VERSION ""

NS_ :

BS_:

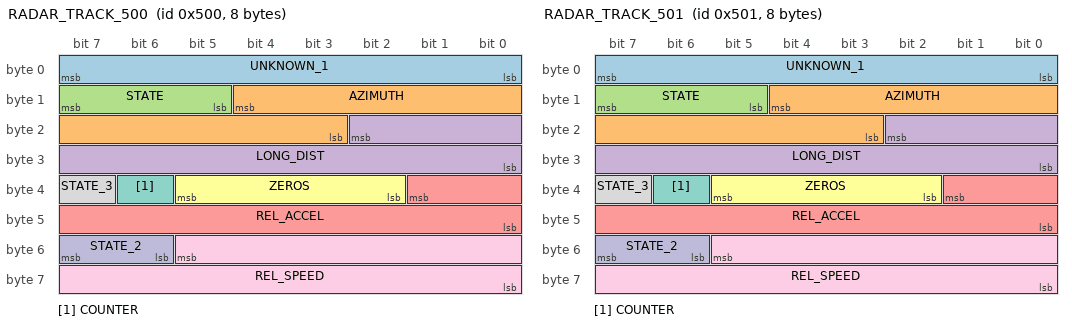
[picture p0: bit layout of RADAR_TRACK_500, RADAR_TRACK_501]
BO_ 1280 RADAR_TRACK_500: 8 RADAR
 SG_ UNKNOWN_1 : 7|8@0- (1,0) [-128|127] "" XXX
 SG_ AZIMUTH : 12|10@0- (0.2,0) [-102.4|102.2] "" XXX
 SG_ STATE : 15|3@0+ (1,0) [0|7] "" XXX
 SG_ LONG_DIST : 18|11@0+ (0.1,0) [0|204.7] "" XXX
 SG_ REL_ACCEL : 33|10@0- (0.02,0) [-10.24|10.22] "" XXX
 SG_ ZEROS : 37|4@0+ (1,0) [0|255] "" XXX
 SG_ COUNTER : 38|1@0+ (1,0) [0|1] "" XXX
 SG_ STATE_3 : 39|1@0+ (1,0) [0|1] "" XXX
 SG_ REL_SPEED : 53|14@0- (0.01,0) [-81.92|81.92] "" XXX
 SG_ STATE_2 : 55|2@0+ (1,0) [0|3] "" XXX

BO_ 1281 RADAR_TRACK_501: 8 RADAR
 SG_ UNKNOWN_1 : 7|8@0- (1,0) [-128|127] "" XXX
 SG_ AZIMUTH : 12|10@0- (0.2,0) [-102.4|102.2] "" XXX
 SG_ STATE : 15|3@0+ (1,0) [0|7] "" XXX
 SG_ LONG_DIST : 18|11@0+ (0.1,0) [0|204.7] "" XXX
 SG_ REL_ACCEL : 33|10@0- (0.02,0) [-10.24|10.22] "" XXX
 SG_ ZEROS : 37|4@0+ (1,0) [0|255] "" XXX
 SG_ COUNTER : 38|1@0+ (1,0) [0|1] "" XXX
 SG_ STATE_3 : 39|1@0+ (1,0) [0|1] "" XXX
 SG_ REL_SPEED : 53|14@0- (0.01,0) [-81.92|81.92] "" XXX
 SG_ STATE_2 : 55|2@0+ (1,0) [0|3] "" XXX

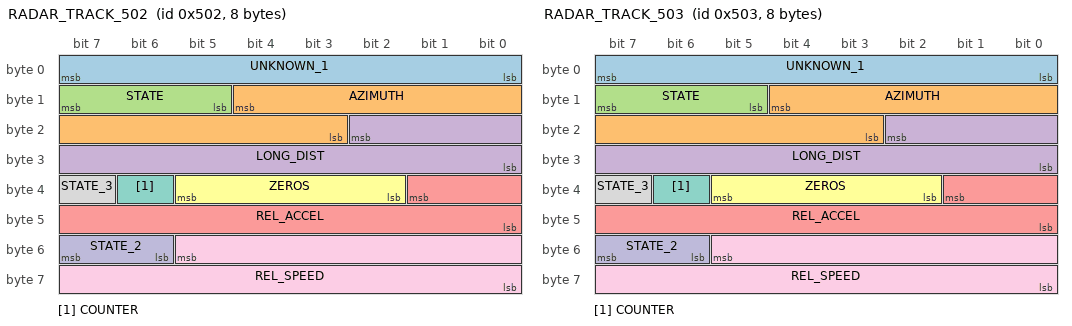
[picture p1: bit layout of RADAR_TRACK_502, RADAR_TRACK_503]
BO_ 1282 RADAR_TRACK_502: 8 RADAR
 SG_ UNKNOWN_1 : 7|8@0- (1,0) [-128|127] "" XXX
 SG_ AZIMUTH : 12|10@0- (0.2,0) [-102.4|102.2] "" XXX
 SG_ STATE : 15|3@0+ (1,0) [0|7] "" XXX
 SG_ LONG_DIST : 18|11@0+ (0.1,0) [0|204.7] "" XXX
 SG_ REL_ACCEL : 33|10@0- (0.02,0) [-10.24|10.22] "" XXX
 SG_ ZEROS : 37|4@0+ (1,0) [0|255] "" XXX
 SG_ COUNTER : 38|1@0+ (1,0) [0|1] "" XXX
 SG_ STATE_3 : 39|1@0+ (1,0) [0|1] "" XXX
 SG_ REL_SPEED : 53|14@0- (0.01,0) [-81.92|81.92] "" XXX
 SG_ STATE_2 : 55|2@0+ (1,0) [0|3] "" XXX

BO_ 1283 RADAR_TRACK_503: 8 RADAR
 SG_ UNKNOWN_1 : 7|8@0- (1,0) [-128|127] "" XXX
 SG_ AZIMUTH : 12|10@0- (0.2,0) [-102.4|102.2] "" XXX
 SG_ STATE : 15|3@0+ (1,0) [0|7] "" XXX
 SG_ LONG_DIST : 18|11@0+ (0.1,0) [0|204.7] "" XXX
 SG_ REL_ACCEL : 33|10@0- (0.02,0) [-10.24|10.22] "" XXX
 SG_ ZEROS : 37|4@0+ (1,0) [0|255] "" XXX
 SG_ COUNTER : 38|1@0+ (1,0) [0|1] "" XXX
 SG_ STATE_3 : 39|1@0+ (1,0) [0|1] "" XXX
 SG_ REL_SPEED : 53|14@0- (0.01,0) [-81.92|81.92] "" XXX
 SG_ STATE_2 : 55|2@0+ (1,0) [0|3] "" XXX

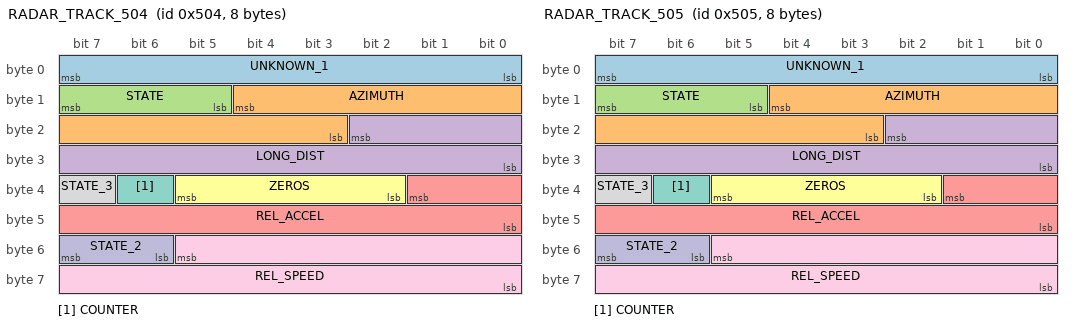
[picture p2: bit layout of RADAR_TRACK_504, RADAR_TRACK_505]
BO_ 1284 RADAR_TRACK_504: 8 RADAR
 SG_ UNKNOWN_1 : 7|8@0- (1,0) [-128|127] "" XXX
 SG_ AZIMUTH : 12|10@0- (0.2,0) [-102.4|102.2] "" XXX
 SG_ STATE : 15|3@0+ (1,0) [0|7] "" XXX
 SG_ LONG_DIST : 18|11@0+ (0.1,0) [0|204.7] "" XXX
 SG_ REL_ACCEL : 33|10@0- (0.02,0) [-10.24|10.22] "" XXX
 SG_ ZEROS : 37|4@0+ (1,0) [0|255] "" XXX
 SG_ COUNTER : 38|1@0+ (1,0) [0|1] "" XXX
 SG_ STATE_3 : 39|1@0+ (1,0) [0|1] "" XXX
 SG_ REL_SPEED : 53|14@0- (0.01,0) [-81.92|81.92] "" XXX
 SG_ STATE_2 : 55|2@0+ (1,0) [0|3] "" XXX

BO_ 1285 RADAR_TRACK_505: 8 RADAR
 SG_ UNKNOWN_1 : 7|8@0- (1,0) [-128|127] "" XXX
 SG_ AZIMUTH : 12|10@0- (0.2,0) [-102.4|102.2] "" XXX
 SG_ STATE : 15|3@0+ (1,0) [0|7] "" XXX
 SG_ LONG_DIST : 18|11@0+ (0.1,0) [0|204.7] "" XXX
 SG_ REL_ACCEL : 33|10@0- (0.02,0) [-10.24|10.22] "" XXX
 SG_ ZEROS : 37|4@0+ (1,0) [0|255] "" XXX
 SG_ COUNTER : 38|1@0+ (1,0) [0|1] "" XXX
 SG_ STATE_3 : 39|1@0+ (1,0) [0|1] "" XXX
 SG_ REL_SPEED : 53|14@0- (0.01,0) [-81.92|81.92] "" XXX
 SG_ STATE_2 : 55|2@0+ (1,0) [0|3] "" XXX

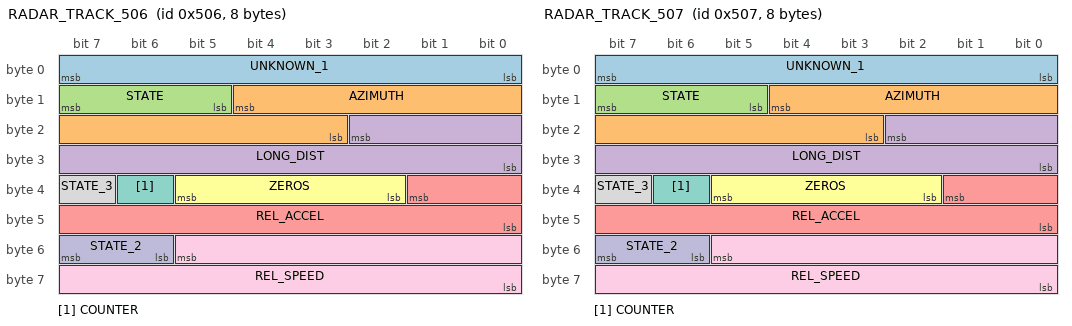
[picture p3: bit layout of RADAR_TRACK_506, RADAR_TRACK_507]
BO_ 1286 RADAR_TRACK_506: 8 RADAR
 SG_ UNKNOWN_1 : 7|8@0- (1,0) [-128|127] "" XXX
 SG_ AZIMUTH : 12|10@0- (0.2,0) [-102.4|102.2] "" XXX
 SG_ STATE : 15|3@0+ (1,0) [0|7] "" XXX
 SG_ LONG_DIST : 18|11@0+ (0.1,0) [0|204.7] "" XXX
 SG_ REL_ACCEL : 33|10@0- (0.02,0) [-10.24|10.22] "" XXX
 SG_ ZEROS : 37|4@0+ (1,0) [0|255] "" XXX
 SG_ COUNTER : 38|1@0+ (1,0) [0|1] "" XXX
 SG_ STATE_3 : 39|1@0+ (1,0) [0|1] "" XXX
 SG_ REL_SPEED : 53|14@0- (0.01,0) [-81.92|81.92] "" XXX
 SG_ STATE_2 : 55|2@0+ (1,0) [0|3] "" XXX

BO_ 1287 RADAR_TRACK_507: 8 RADAR
 SG_ UNKNOWN_1 : 7|8@0- (1,0) [-128|127] "" XXX
 SG_ AZIMUTH : 12|10@0- (0.2,0) [-102.4|102.2] "" XXX
 SG_ STATE : 15|3@0+ (1,0) [0|7] "" XXX
 SG_ LONG_DIST : 18|11@0+ (0.1,0) [0|204.7] "" XXX
 SG_ REL_ACCEL : 33|10@0- (0.02,0) [-10.24|10.22] "" XXX
 SG_ ZEROS : 37|4@0+ (1,0) [0|255] "" XXX
 SG_ COUNTER : 38|1@0+ (1,0) [0|1] "" XXX
 SG_ STATE_3 : 39|1@0+ (1,0) [0|1] "" XXX
 SG_ REL_SPEED : 53|14@0- (0.01,0) [-81.92|81.92] "" XXX
 SG_ STATE_2 : 55|2@0+ (1,0) [0|3] "" XXX

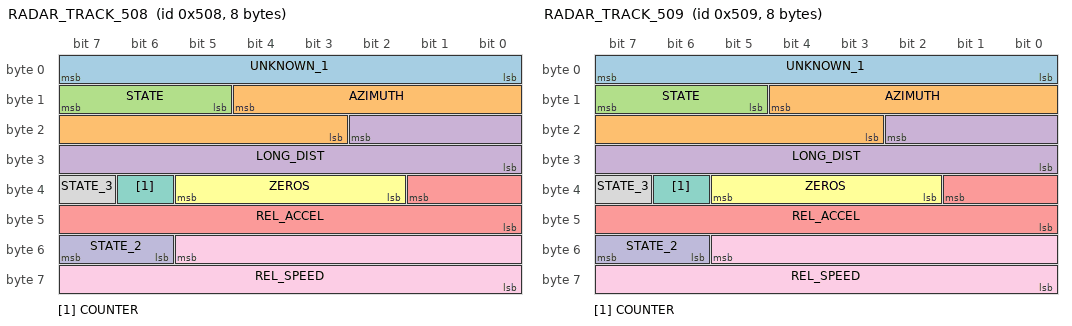
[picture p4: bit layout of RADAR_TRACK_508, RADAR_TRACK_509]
BO_ 1288 RADAR_TRACK_508: 8 RADAR
 SG_ UNKNOWN_1 : 7|8@0- (1,0) [-128|127] "" XXX
 SG_ AZIMUTH : 12|10@0- (0.2,0) [-102.4|102.2] "" XXX
 SG_ STATE : 15|3@0+ (1,0) [0|7] "" XXX
 SG_ LONG_DIST : 18|11@0+ (0.1,0) [0|204.7] "" XXX
 SG_ REL_ACCEL : 33|10@0- (0.02,0) [-10.24|10.22] "" XXX
 SG_ ZEROS : 37|4@0+ (1,0) [0|255] "" XXX
 SG_ COUNTER : 38|1@0+ (1,0) [0|1] "" XXX
 SG_ STATE_3 : 39|1@0+ (1,0) [0|1] "" XXX
 SG_ REL_SPEED : 53|14@0- (0.01,0) [-81.92|81.92] "" XXX
 SG_ STATE_2 : 55|2@0+ (1,0) [0|3] "" XXX

BO_ 1289 RADAR_TRACK_509: 8 RADAR
 SG_ UNKNOWN_1 : 7|8@0- (1,0) [-128|127] "" XXX
 SG_ AZIMUTH : 12|10@0- (0.2,0) [-102.4|102.2] "" XXX
 SG_ STATE : 15|3@0+ (1,0) [0|7] "" XXX
 SG_ LONG_DIST : 18|11@0+ (0.1,0) [0|204.7] "" XXX
 SG_ REL_ACCEL : 33|10@0- (0.02,0) [-10.24|10.22] "" XXX
 SG_ ZEROS : 37|4@0+ (1,0) [0|255] "" XXX
 SG_ COUNTER : 38|1@0+ (1,0) [0|1] "" XXX
 SG_ STATE_3 : 39|1@0+ (1,0) [0|1] "" XXX
 SG_ REL_SPEED : 53|14@0- (0.01,0) [-81.92|81.92] "" XXX
 SG_ STATE_2 : 55|2@0+ (1,0) [0|3] "" XXX

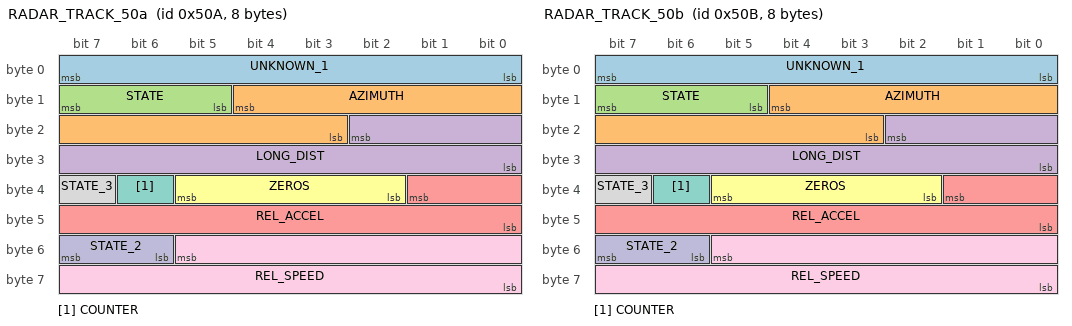
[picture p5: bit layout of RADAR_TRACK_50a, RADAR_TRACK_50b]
BO_ 1290 RADAR_TRACK_50a: 8 RADAR
 SG_ UNKNOWN_1 : 7|8@0- (1,0) [-128|127] "" XXX
 SG_ AZIMUTH : 12|10@0- (0.2,0) [-102.4|102.2] "" XXX
 SG_ STATE : 15|3@0+ (1,0) [0|7] "" XXX
 SG_ LONG_DIST : 18|11@0+ (0.1,0) [0|204.7] "" XXX
 SG_ REL_ACCEL : 33|10@0- (0.02,0) [-10.24|10.22] "" XXX
 SG_ ZEROS : 37|4@0+ (1,0) [0|255] "" XXX
 SG_ COUNTER : 38|1@0+ (1,0) [0|1] "" XXX
 SG_ STATE_3 : 39|1@0+ (1,0) [0|1] "" XXX
 SG_ REL_SPEED : 53|14@0- (0.01,0) [-81.92|81.92] "" XXX
 SG_ STATE_2 : 55|2@0+ (1,0) [0|3] "" XXX

BO_ 1291 RADAR_TRACK_50b: 8 RADAR
 SG_ UNKNOWN_1 : 7|8@0- (1,0) [-128|127] "" XXX
 SG_ AZIMUTH : 12|10@0- (0.2,0) [-102.4|102.2] "" XXX
 SG_ STATE : 15|3@0+ (1,0) [0|7] "" XXX
 SG_ LONG_DIST : 18|11@0+ (0.1,0) [0|204.7] "" XXX
 SG_ REL_ACCEL : 33|10@0- (0.02,0) [-10.24|10.22] "" XXX
 SG_ ZEROS : 37|4@0+ (1,0) [0|255] "" XXX
 SG_ COUNTER : 38|1@0+ (1,0) [0|1] "" XXX
 SG_ STATE_3 : 39|1@0+ (1,0) [0|1] "" XXX
 SG_ REL_SPEED : 53|14@0- (0.01,0) [-81.92|81.92] "" XXX
 SG_ STATE_2 : 55|2@0+ (1,0) [0|3] "" XXX

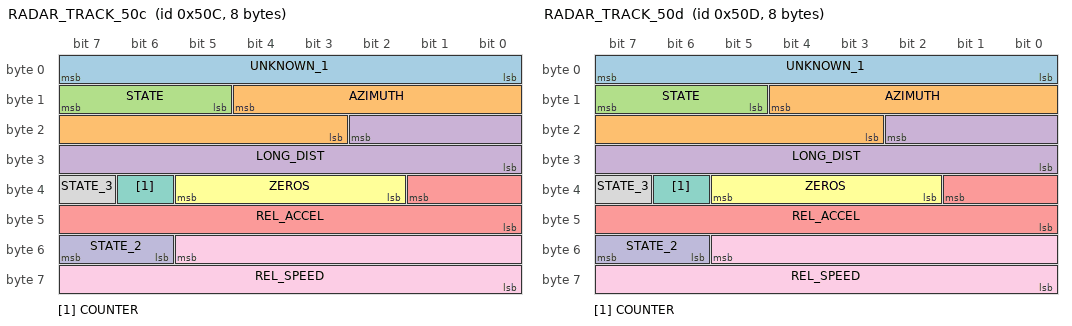
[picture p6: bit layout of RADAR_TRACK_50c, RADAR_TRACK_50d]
BO_ 1292 RADAR_TRACK_50c: 8 RADAR
 SG_ UNKNOWN_1 : 7|8@0- (1,0) [-128|127] "" XXX
 SG_ AZIMUTH : 12|10@0- (0.2,0) [-102.4|102.2] "" XXX
 SG_ STATE : 15|3@0+ (1,0) [0|7] "" XXX
 SG_ LONG_DIST : 18|11@0+ (0.1,0) [0|204.7] "" XXX
 SG_ REL_ACCEL : 33|10@0- (0.02,0) [-10.24|10.22] "" XXX
 SG_ ZEROS : 37|4@0+ (1,0) [0|255] "" XXX
 SG_ COUNTER : 38|1@0+ (1,0) [0|1] "" XXX
 SG_ STATE_3 : 39|1@0+ (1,0) [0|1] "" XXX
 SG_ REL_SPEED : 53|14@0- (0.01,0) [-81.92|81.92] "" XXX
 SG_ STATE_2 : 55|2@0+ (1,0) [0|3] "" XXX

BO_ 1293 RADAR_TRACK_50d: 8 RADAR
 SG_ UNKNOWN_1 : 7|8@0- (1,0) [-128|127] "" XXX
 SG_ AZIMUTH : 12|10@0- (0.2,0) [-102.4|102.2] "" XXX
 SG_ STATE : 15|3@0+ (1,0) [0|7] "" XXX
 SG_ LONG_DIST : 18|11@0+ (0.1,0) [0|204.7] "" XXX
 SG_ REL_ACCEL : 33|10@0- (0.02,0) [-10.24|10.22] "" XXX
 SG_ ZEROS : 37|4@0+ (1,0) [0|255] "" XXX
 SG_ COUNTER : 38|1@0+ (1,0) [0|1] "" XXX
 SG_ STATE_3 : 39|1@0+ (1,0) [0|1] "" XXX
 SG_ REL_SPEED : 53|14@0- (0.01,0) [-81.92|81.92] "" XXX
 SG_ STATE_2 : 55|2@0+ (1,0) [0|3] "" XXX

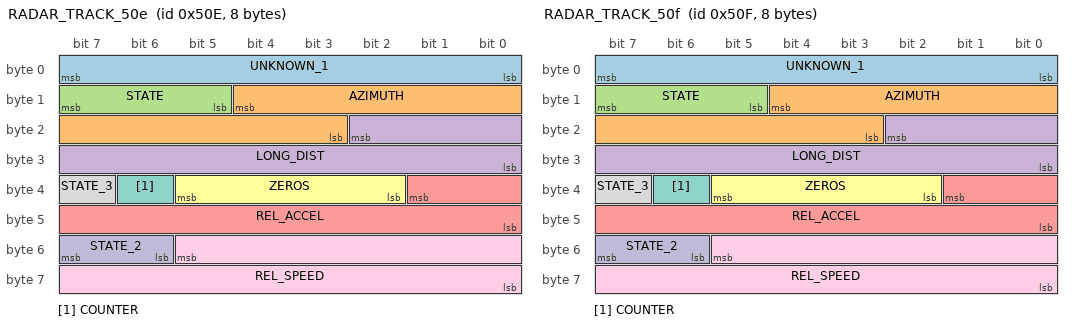
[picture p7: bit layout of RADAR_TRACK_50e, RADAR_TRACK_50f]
BO_ 1294 RADAR_TRACK_50e: 8 RADAR
 SG_ UNKNOWN_1 : 7|8@0- (1,0) [-128|127] "" XXX
 SG_ AZIMUTH : 12|10@0- (0.2,0) [-102.4|102.2] "" XXX
 SG_ STATE : 15|3@0+ (1,0) [0|7] "" XXX
 SG_ LONG_DIST : 18|11@0+ (0.1,0) [0|204.7] "" XXX
 SG_ REL_ACCEL : 33|10@0- (0.02,0) [-10.24|10.22] "" XXX
 SG_ ZEROS : 37|4@0+ (1,0) [0|255] "" XXX
 SG_ COUNTER : 38|1@0+ (1,0) [0|1] "" XXX
 SG_ STATE_3 : 39|1@0+ (1,0) [0|1] "" XXX
 SG_ REL_SPEED : 53|14@0- (0.01,0) [-81.92|81.92] "" XXX
 SG_ STATE_2 : 55|2@0+ (1,0) [0|3] "" XXX

BO_ 1295 RADAR_TRACK_50f: 8 RADAR
 SG_ UNKNOWN_1 : 7|8@0- (1,0) [-128|127] "" XXX
 SG_ AZIMUTH : 12|10@0- (0.2,0) [-102.4|102.2] "" XXX
 SG_ STATE : 15|3@0+ (1,0) [0|7] "" XXX
 SG_ LONG_DIST : 18|11@0+ (0.1,0) [0|204.7] "" XXX
 SG_ REL_ACCEL : 33|10@0- (0.02,0) [-10.24|10.22] "" XXX
 SG_ ZEROS : 37|4@0+ (1,0) [0|255] "" XXX
 SG_ COUNTER : 38|1@0+ (1,0) [0|1] "" XXX
 SG_ STATE_3 : 39|1@0+ (1,0) [0|1] "" XXX
 SG_ REL_SPEED : 53|14@0- (0.01,0) [-81.92|81.92] "" XXX
 SG_ STATE_2 : 55|2@0+ (1,0) [0|3] "" XXX

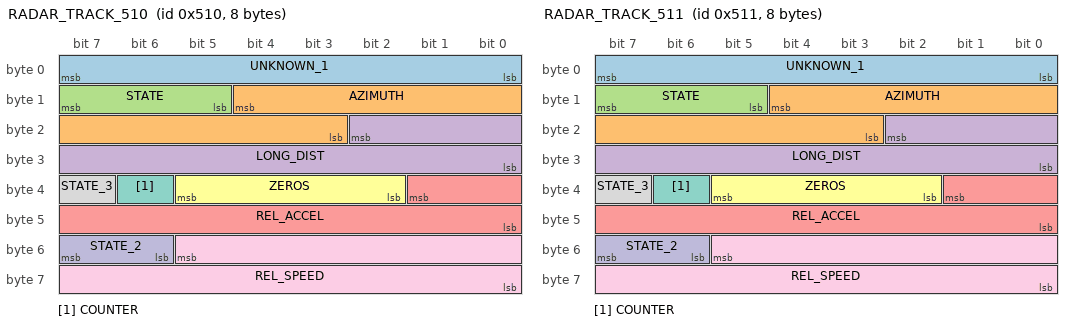
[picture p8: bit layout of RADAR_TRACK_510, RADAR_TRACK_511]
BO_ 1296 RADAR_TRACK_510: 8 RADAR
 SG_ UNKNOWN_1 : 7|8@0- (1,0) [-128|127] "" XXX
 SG_ AZIMUTH : 12|10@0- (0.2,0) [-102.4|102.2] "" XXX
 SG_ STATE : 15|3@0+ (1,0) [0|7] "" XXX
 SG_ LONG_DIST : 18|11@0+ (0.1,0) [0|204.7] "" XXX
 SG_ REL_ACCEL : 33|10@0- (0.02,0) [-10.24|10.22] "" XXX
 SG_ ZEROS : 37|4@0+ (1,0) [0|255] "" XXX
 SG_ COUNTER : 38|1@0+ (1,0) [0|1] "" XXX
 SG_ STATE_3 : 39|1@0+ (1,0) [0|1] "" XXX
 SG_ REL_SPEED : 53|14@0- (0.01,0) [-81.92|81.92] "" XXX
 SG_ STATE_2 : 55|2@0+ (1,0) [0|3] "" XXX

BO_ 1297 RADAR_TRACK_511: 8 RADAR
 SG_ UNKNOWN_1 : 7|8@0- (1,0) [-128|127] "" XXX
 SG_ AZIMUTH : 12|10@0- (0.2,0) [-102.4|102.2] "" XXX
 SG_ STATE : 15|3@0+ (1,0) [0|7] "" XXX
 SG_ LONG_DIST : 18|11@0+ (0.1,0) [0|204.7] "" XXX
 SG_ REL_ACCEL : 33|10@0- (0.02,0) [-10.24|10.22] "" XXX
 SG_ ZEROS : 37|4@0+ (1,0) [0|255] "" XXX
 SG_ COUNTER : 38|1@0+ (1,0) [0|1] "" XXX
 SG_ STATE_3 : 39|1@0+ (1,0) [0|1] "" XXX
 SG_ REL_SPEED : 53|14@0- (0.01,0) [-81.92|81.92] "" XXX
 SG_ STATE_2 : 55|2@0+ (1,0) [0|3] "" XXX

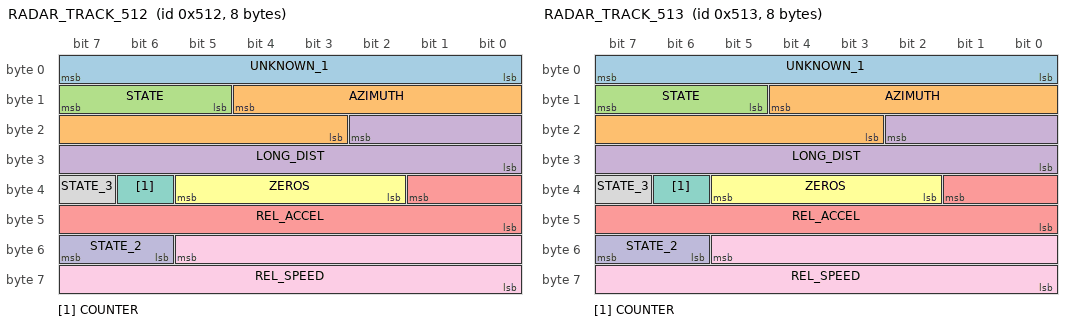
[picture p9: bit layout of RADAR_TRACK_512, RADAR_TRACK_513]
BO_ 1298 RADAR_TRACK_512: 8 RADAR
 SG_ UNKNOWN_1 : 7|8@0- (1,0) [-128|127] "" XXX
 SG_ AZIMUTH : 12|10@0- (0.2,0) [-102.4|102.2] "" XXX
 SG_ STATE : 15|3@0+ (1,0) [0|7] "" XXX
 SG_ LONG_DIST : 18|11@0+ (0.1,0) [0|204.7] "" XXX
 SG_ REL_ACCEL : 33|10@0- (0.02,0) [-10.24|10.22] "" XXX
 SG_ ZEROS : 37|4@0+ (1,0) [0|255] "" XXX
 SG_ COUNTER : 38|1@0+ (1,0) [0|1] "" XXX
 SG_ STATE_3 : 39|1@0+ (1,0) [0|1] "" XXX
 SG_ REL_SPEED : 53|14@0- (0.01,0) [-81.92|81.92] "" XXX
 SG_ STATE_2 : 55|2@0+ (1,0) [0|3] "" XXX

BO_ 1299 RADAR_TRACK_513: 8 RADAR
 SG_ UNKNOWN_1 : 7|8@0- (1,0) [-128|127] "" XXX
 SG_ AZIMUTH : 12|10@0- (0.2,0) [-102.4|102.2] "" XXX
 SG_ STATE : 15|3@0+ (1,0) [0|7] "" XXX
 SG_ LONG_DIST : 18|11@0+ (0.1,0) [0|204.7] "" XXX
 SG_ REL_ACCEL : 33|10@0- (0.02,0) [-10.24|10.22] "" XXX
 SG_ ZEROS : 37|4@0+ (1,0) [0|255] "" XXX
 SG_ COUNTER : 38|1@0+ (1,0) [0|1] "" XXX
 SG_ STATE_3 : 39|1@0+ (1,0) [0|1] "" XXX
 SG_ REL_SPEED : 53|14@0- (0.01,0) [-81.92|81.92] "" XXX
 SG_ STATE_2 : 55|2@0+ (1,0) [0|3] "" XXX

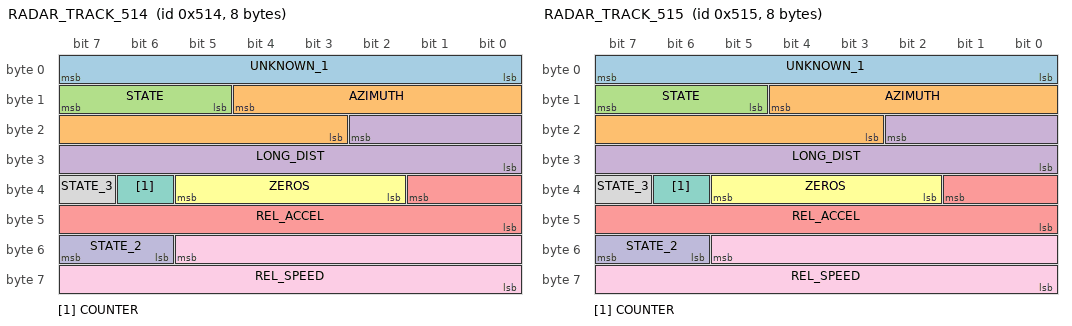
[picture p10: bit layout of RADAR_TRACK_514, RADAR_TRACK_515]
BO_ 1300 RADAR_TRACK_514: 8 RADAR
 SG_ UNKNOWN_1 : 7|8@0- (1,0) [-128|127] "" XXX
 SG_ AZIMUTH : 12|10@0- (0.2,0) [-102.4|102.2] "" XXX
 SG_ STATE : 15|3@0+ (1,0) [0|7] "" XXX
 SG_ LONG_DIST : 18|11@0+ (0.1,0) [0|204.7] "" XXX
 SG_ REL_ACCEL : 33|10@0- (0.02,0) [-10.24|10.22] "" XXX
 SG_ ZEROS : 37|4@0+ (1,0) [0|255] "" XXX
 SG_ COUNTER : 38|1@0+ (1,0) [0|1] "" XXX
 SG_ STATE_3 : 39|1@0+ (1,0) [0|1] "" XXX
 SG_ REL_SPEED : 53|14@0- (0.01,0) [-81.92|81.92] "" XXX
 SG_ STATE_2 : 55|2@0+ (1,0) [0|3] "" XXX

BO_ 1301 RADAR_TRACK_515: 8 RADAR
 SG_ UNKNOWN_1 : 7|8@0- (1,0) [-128|127] "" XXX
 SG_ AZIMUTH : 12|10@0- (0.2,0) [-102.4|102.2] "" XXX
 SG_ STATE : 15|3@0+ (1,0) [0|7] "" XXX
 SG_ LONG_DIST : 18|11@0+ (0.1,0) [0|204.7] "" XXX
 SG_ REL_ACCEL : 33|10@0- (0.02,0) [-10.24|10.22] "" XXX
 SG_ ZEROS : 37|4@0+ (1,0) [0|255] "" XXX
 SG_ COUNTER : 38|1@0+ (1,0) [0|1] "" XXX
 SG_ STATE_3 : 39|1@0+ (1,0) [0|1] "" XXX
 SG_ REL_SPEED : 53|14@0- (0.01,0) [-81.92|81.92] "" XXX
 SG_ STATE_2 : 55|2@0+ (1,0) [0|3] "" XXX

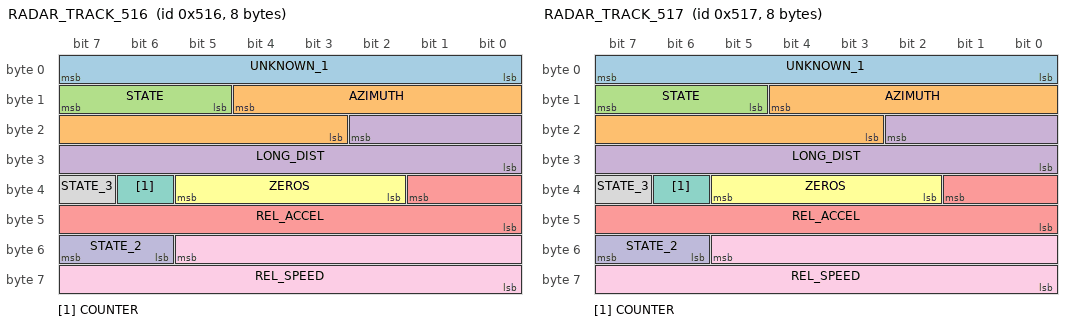
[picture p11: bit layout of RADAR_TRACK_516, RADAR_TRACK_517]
BO_ 1302 RADAR_TRACK_516: 8 RADAR
 SG_ UNKNOWN_1 : 7|8@0- (1,0) [-128|127] "" XXX
 SG_ AZIMUTH : 12|10@0- (0.2,0) [-102.4|102.2] "" XXX
 SG_ STATE : 15|3@0+ (1,0) [0|7] "" XXX
 SG_ LONG_DIST : 18|11@0+ (0.1,0) [0|204.7] "" XXX
 SG_ REL_ACCEL : 33|10@0- (0.02,0) [-10.24|10.22] "" XXX
 SG_ ZEROS : 37|4@0+ (1,0) [0|255] "" XXX
 SG_ COUNTER : 38|1@0+ (1,0) [0|1] "" XXX
 SG_ STATE_3 : 39|1@0+ (1,0) [0|1] "" XXX
 SG_ REL_SPEED : 53|14@0- (0.01,0) [-81.92|81.92] "" XXX
 SG_ STATE_2 : 55|2@0+ (1,0) [0|3] "" XXX

BO_ 1303 RADAR_TRACK_517: 8 RADAR
 SG_ UNKNOWN_1 : 7|8@0- (1,0) [-128|127] "" XXX
 SG_ AZIMUTH : 12|10@0- (0.2,0) [-102.4|102.2] "" XXX
 SG_ STATE : 15|3@0+ (1,0) [0|7] "" XXX
 SG_ LONG_DIST : 18|11@0+ (0.1,0) [0|204.7] "" XXX
 SG_ REL_ACCEL : 33|10@0- (0.02,0) [-10.24|10.22] "" XXX
 SG_ ZEROS : 37|4@0+ (1,0) [0|255] "" XXX
 SG_ COUNTER : 38|1@0+ (1,0) [0|1] "" XXX
 SG_ STATE_3 : 39|1@0+ (1,0) [0|1] "" XXX
 SG_ REL_SPEED : 53|14@0- (0.01,0) [-81.92|81.92] "" XXX
 SG_ STATE_2 : 55|2@0+ (1,0) [0|3] "" XXX

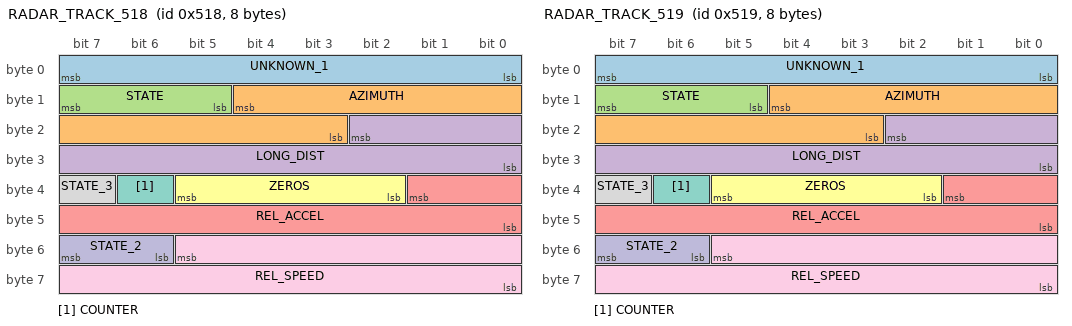
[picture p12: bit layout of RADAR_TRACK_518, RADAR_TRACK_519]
BO_ 1304 RADAR_TRACK_518: 8 RADAR
 SG_ UNKNOWN_1 : 7|8@0- (1,0) [-128|127] "" XXX
 SG_ AZIMUTH : 12|10@0- (0.2,0) [-102.4|102.2] "" XXX
 SG_ STATE : 15|3@0+ (1,0) [0|7] "" XXX
 SG_ LONG_DIST : 18|11@0+ (0.1,0) [0|204.7] "" XXX
 SG_ REL_ACCEL : 33|10@0- (0.02,0) [-10.24|10.22] "" XXX
 SG_ ZEROS : 37|4@0+ (1,0) [0|255] "" XXX
 SG_ COUNTER : 38|1@0+ (1,0) [0|1] "" XXX
 SG_ STATE_3 : 39|1@0+ (1,0) [0|1] "" XXX
 SG_ REL_SPEED : 53|14@0- (0.01,0) [-81.92|81.92] "" XXX
 SG_ STATE_2 : 55|2@0+ (1,0) [0|3] "" XXX

BO_ 1305 RADAR_TRACK_519: 8 RADAR
 SG_ UNKNOWN_1 : 7|8@0- (1,0) [-128|127] "" XXX
 SG_ AZIMUTH : 12|10@0- (0.2,0) [-102.4|102.2] "" XXX
 SG_ STATE : 15|3@0+ (1,0) [0|7] "" XXX
 SG_ LONG_DIST : 18|11@0+ (0.1,0) [0|204.7] "" XXX
 SG_ REL_ACCEL : 33|10@0- (0.02,0) [-10.24|10.22] "" XXX
 SG_ ZEROS : 37|4@0+ (1,0) [0|255] "" XXX
 SG_ COUNTER : 38|1@0+ (1,0) [0|1] "" XXX
 SG_ STATE_3 : 39|1@0+ (1,0) [0|1] "" XXX
 SG_ REL_SPEED : 53|14@0- (0.01,0) [-81.92|81.92] "" XXX
 SG_ STATE_2 : 55|2@0+ (1,0) [0|3] "" XXX

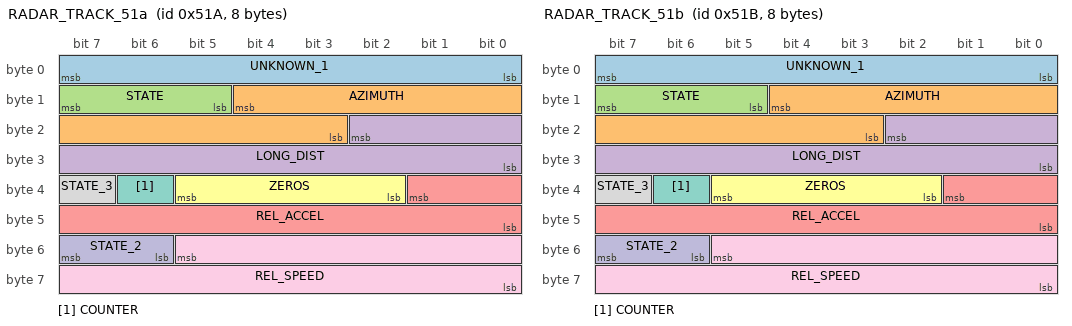
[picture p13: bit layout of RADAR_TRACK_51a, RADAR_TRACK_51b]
BO_ 1306 RADAR_TRACK_51a: 8 RADAR
 SG_ UNKNOWN_1 : 7|8@0- (1,0) [-128|127] "" XXX
 SG_ AZIMUTH : 12|10@0- (0.2,0) [-102.4|102.2] "" XXX
 SG_ STATE : 15|3@0+ (1,0) [0|7] "" XXX
 SG_ LONG_DIST : 18|11@0+ (0.1,0) [0|204.7] "" XXX
 SG_ REL_ACCEL : 33|10@0- (0.02,0) [-10.24|10.22] "" XXX
 SG_ ZEROS : 37|4@0+ (1,0) [0|255] "" XXX
 SG_ COUNTER : 38|1@0+ (1,0) [0|1] "" XXX
 SG_ STATE_3 : 39|1@0+ (1,0) [0|1] "" XXX
 SG_ REL_SPEED : 53|14@0- (0.01,0) [-81.92|81.92] "" XXX
 SG_ STATE_2 : 55|2@0+ (1,0) [0|3] "" XXX

BO_ 1307 RADAR_TRACK_51b: 8 RADAR
 SG_ UNKNOWN_1 : 7|8@0- (1,0) [-128|127] "" XXX
 SG_ AZIMUTH : 12|10@0- (0.2,0) [-102.4|102.2] "" XXX
 SG_ STATE : 15|3@0+ (1,0) [0|7] "" XXX
 SG_ LONG_DIST : 18|11@0+ (0.1,0) [0|204.7] "" XXX
 SG_ REL_ACCEL : 33|10@0- (0.02,0) [-10.24|10.22] "" XXX
 SG_ ZEROS : 37|4@0+ (1,0) [0|255] "" XXX
 SG_ COUNTER : 38|1@0+ (1,0) [0|1] "" XXX
 SG_ STATE_3 : 39|1@0+ (1,0) [0|1] "" XXX
 SG_ REL_SPEED : 53|14@0- (0.01,0) [-81.92|81.92] "" XXX
 SG_ STATE_2 : 55|2@0+ (1,0) [0|3] "" XXX

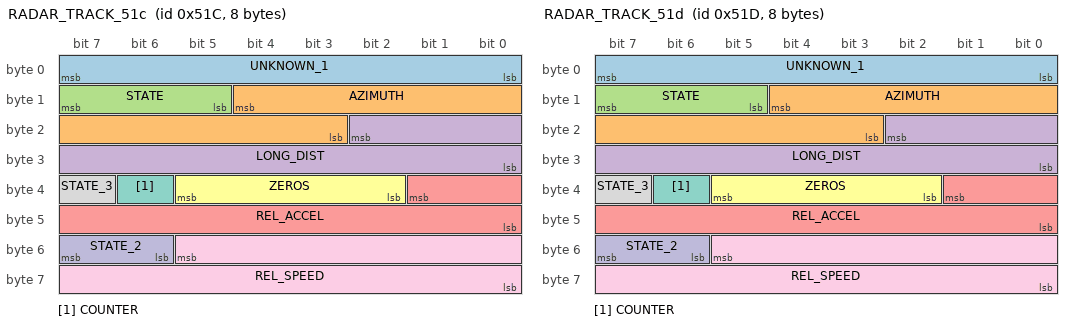
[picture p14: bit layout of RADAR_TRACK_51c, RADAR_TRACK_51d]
BO_ 1308 RADAR_TRACK_51c: 8 RADAR
 SG_ UNKNOWN_1 : 7|8@0- (1,0) [-128|127] "" XXX
 SG_ AZIMUTH : 12|10@0- (0.2,0) [-102.4|102.2] "" XXX
 SG_ STATE : 15|3@0+ (1,0) [0|7] "" XXX
 SG_ LONG_DIST : 18|11@0+ (0.1,0) [0|204.7] "" XXX
 SG_ REL_ACCEL : 33|10@0- (0.02,0) [-10.24|10.22] "" XXX
 SG_ ZEROS : 37|4@0+ (1,0) [0|255] "" XXX
 SG_ COUNTER : 38|1@0+ (1,0) [0|1] "" XXX
 SG_ STATE_3 : 39|1@0+ (1,0) [0|1] "" XXX
 SG_ REL_SPEED : 53|14@0- (0.01,0) [-81.92|81.92] "" XXX
 SG_ STATE_2 : 55|2@0+ (1,0) [0|3] "" XXX

BO_ 1309 RADAR_TRACK_51d: 8 RADAR
 SG_ UNKNOWN_1 : 7|8@0- (1,0) [-128|127] "" XXX
 SG_ AZIMUTH : 12|10@0- (0.2,0) [-102.4|102.2] "" XXX
 SG_ STATE : 15|3@0+ (1,0) [0|7] "" XXX
 SG_ LONG_DIST : 18|11@0+ (0.1,0) [0|204.7] "" XXX
 SG_ REL_ACCEL : 33|10@0- (0.02,0) [-10.24|10.22] "" XXX
 SG_ ZEROS : 37|4@0+ (1,0) [0|255] "" XXX
 SG_ COUNTER : 38|1@0+ (1,0) [0|1] "" XXX
 SG_ STATE_3 : 39|1@0+ (1,0) [0|1] "" XXX
 SG_ REL_SPEED : 53|14@0- (0.01,0) [-81.92|81.92] "" XXX
 SG_ STATE_2 : 55|2@0+ (1,0) [0|3] "" XXX

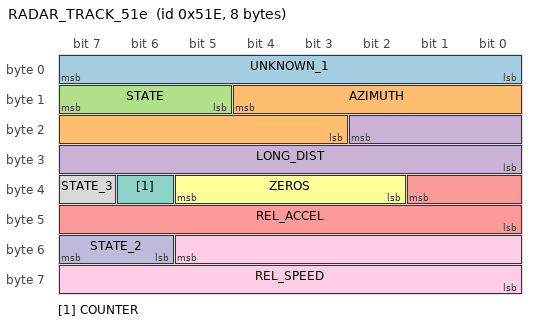
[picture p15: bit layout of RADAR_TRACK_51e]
BO_ 1310 RADAR_TRACK_51e: 8 RADAR
 SG_ UNKNOWN_1 : 7|8@0- (1,0) [-128|127] "" XXX
 SG_ AZIMUTH : 12|10@0- (0.2,0) [-102.4|102.2] "" XXX
 SG_ STATE : 15|3@0+ (1,0) [0|7] "" XXX
 SG_ LONG_DIST : 18|11@0+ (0.1,0) [0|204.7] "" XXX
 SG_ REL_ACCEL : 33|10@0- (0.02,0) [-10.24|10.22] "" XXX
 SG_ ZEROS : 37|4@0+ (1,0) [0|255] "" XXX
 SG_ COUNTER : 38|1@0+ (1,0) [0|1] "" XXX
 SG_ STATE_3 : 39|1@0+ (1,0) [0|1] "" XXX
 SG_ REL_SPEED : 53|14@0- (0.01,0) [-81.92|81.92] "" XXX
 SG_ STATE_2 : 55|2@0+ (1,0) [0|3] "" XXX

VAL_ 53 GEAR 0 "P" 5 "D" 6 "N" 7 "R" ;
VAL_ 64 GEAR 0 "P" 5 "D" 6 "N" 7 "R" ;
VAL_ 69 GEAR 0 "P" 5 "D" 6 "N" 7 "R" ;
VAL_ 112 GEAR 0 "P" 5 "D" 6 "N" 7 "R" ;
VAL_ 80 LKA_ICON 0 "hidden" 1 "grey" 2 "green" 3 "flashing green" ;
VAL_ 80 LKA_MODE 1 "warning only" 2 "assist" 6 "off" ;
VAL_ 96 TRACTION_AND_STABILITY_CONTROL 0 "On" 5 "Limited" 1 "Off";
VAL_ 234 LKA_FAULT 0 "ok" 1 "lka fault" ;
VAL_ 272 LKA_ICON 0 "hidden" 1 "grey" 2 "green" 3 "flashing green" ;
VAL_ 272 LKA_MODE 1 "warning only" 2 "assist" 6 "off" ;
VAL_ 298 LKA_ICON 0 "hidden" 1 "grey" 2 "green" 3 "flashing green" ;
VAL_ 298 LKA_MODE 1 "warning only" 2 "assist" 6 "off" ;
VAL_ 304 PARK_BUTTON 1 "Pressed" 2 "Not Pressed";
VAL_ 304 KNOB_POSITION 1 "R" 2 "N (on R side)" 3 "Centered" 4 "N (on D side)" 5 "D";
VAL_ 304 GEAR 1 "P" 2 "R" 3 "N" 4 "D" ;
VAL_ 352 AEB_SETTING 1 "off" 2 "warning only" 3 "active assist" ;
VAL_ 362 BLINKER_CONTROL 1 "hazards" 2 "hazards button backlight" 3 "left blinkers" 4 "right blinkers";
VAL_ 373 ACCEnable 0 "SCC ready" 1 "SCC temp fault" 2 "SCC permanent fault" 3 "SCC permanent fault, communication issue";
VAL_ 416 ACCMode 0 "off" 1 "enabled" 2 "driver_override" 3 "off_maybe_fault" 4 "cancelled" ;
VAL_ 426 CRUISE_BUTTONS 0 "none" 1 "res_accel" 2 "set_decel" 3 "gap_distance" 4 "pause_resume" ;
VAL_ 463 CRUISE_BUTTONS 0 "none" 1 "res_accel" 2 "set_decel" 3 "gap_distance" 4 "pause_resume" ;
VAL_ 463 RIGHT_PADDLE 0 "Not Pulled" 1 "Pulled";
VAL_ 463 LEFT_PADDLE 0 "Not Pulled" 1 "Pulled";
VAL_ 676 LEFT_LANE_LINE 0 "Not Detected" 1 "Low Confidence" 2 "Medium Confidence" 3 "High Confidence";
VAL_ 676 RIGHT_LANE_LINE 0 "Not Detected" 1 "Low Confidence" 2 "Medium Confidence" 3 "High Confidence";
VAL_ 736 MSLA_STATUS 0 "disabled" 1 "active" 2 "paused";
VAL_ 866 LEFT_LANE_LINE 0 "Not Detected" 1 "Low Confidence" 2 "Medium Confidence" 3 "High Confidence";
VAL_ 866 RIGHT_LANE_LINE 0 "Not Detected" 1 "Low Confidence" 2 "Medium Confidence" 3 "High Confidence";
VAL_ 1041 DRIVER_DOOR 0 "Closed" 1 "Opened";
VAL_ 1041 PASSENGER_DOOR 0 "Closed" 1 "Opened";
VAL_ 1041 DRIVER_REAR_DOOR 0 "Closed" 1 "Opened";
VAL_ 1041 PASSENGER_REAR_DOOR 0 "Closed" 1 "Opened";
VAL_ 1041 DRIVER_SEATBELT 0 "Unlatched" 1 "Latched";
VAL_ 1041 PASSENGER_SEATBELT 0 "Unlatched" 1 "Latched";
VAL_ 1144 DRIVE_MODE2 3 "Set Sport" 1 "Set Normal" 2 "Set Eco";
